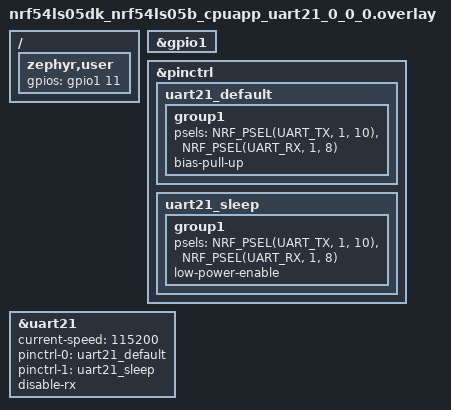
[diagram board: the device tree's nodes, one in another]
/ {
	zephyr,user {
		gpios = <&gpio1 11 GPIO_ACTIVE_HIGH>;
	};
};

&gpio1 {
	status = "okay";
};

&pinctrl {
	uart21_default: uart21_default {
		group1 {
			psels = <NRF_PSEL(UART_TX, 1, 10)>,
				<NRF_PSEL(UART_RX, 1, 8)>;
				bias-pull-up;
		};
	};

	uart21_sleep: uart21_sleep {
		group1 {
			psels = <NRF_PSEL(UART_TX, 1, 10)>,
				<NRF_PSEL(UART_RX, 1, 8)>;
			low-power-enable;
		};
	};
};

dut: &uart21 {
	status = "okay";
	current-speed = <115200>;
	pinctrl-0 = <&uart21_default>;
	pinctrl-1 = <&uart21_sleep>;
	pinctrl-names = "default", "sleep";
	disable-rx;
};
